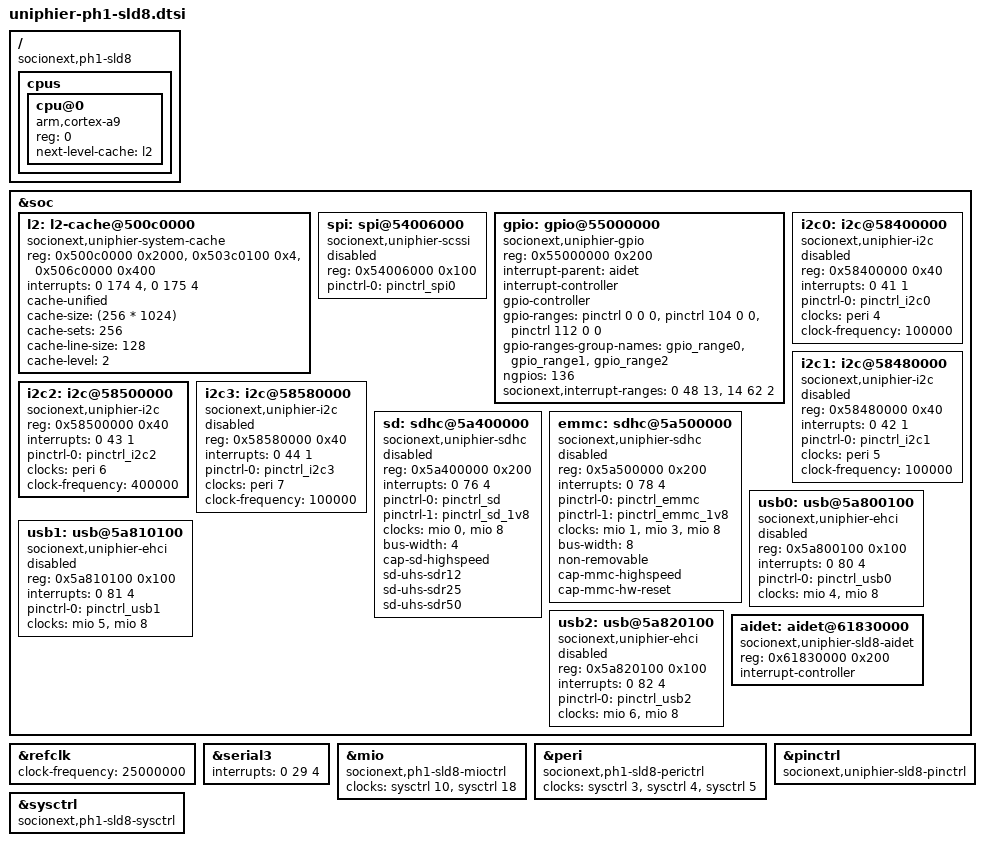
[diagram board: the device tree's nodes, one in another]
// SPDX-License-Identifier: GPL-2.0+ OR MIT
//
// Device Tree Source for UniPhier PH1-sLD8 SoC
//
// Copyright (C) 2015-2016 Socionext Inc.
//   Author: Masahiro Yamada <yamada.masahiro@socionext.com>

#include "uniphier-common32.dtsi"

/ {
	compatible = "socionext,ph1-sld8";

	cpus {
		#address-cells = <1>;
		#size-cells = <0>;

		cpu@0 {
			device_type = "cpu";
			compatible = "arm,cortex-a9";
			reg = <0>;
			next-level-cache = <&l2>;
		};
	};
};

&soc {
	l2: l2-cache@500c0000 {
		compatible = "socionext,uniphier-system-cache";
		reg = <0x500c0000 0x2000>, <0x503c0100 0x4>, <0x506c0000 0x400>;
		interrupts = <0 174 4>, <0 175 4>;
		cache-unified;
		cache-size = <(256 * 1024)>;
		cache-sets = <256>;
		cache-line-size = <128>;
		cache-level = <2>;
	};

	spi: spi@54006000 {
		compatible = "socionext,uniphier-scssi";
		status = "disabled";
		reg = <0x54006000 0x100>;
		pinctrl-names = "default";
		pinctrl-0 = <&pinctrl_spi0>;
	};

	gpio: gpio@55000000 {
		compatible = "socionext,uniphier-gpio";
		reg = <0x55000000 0x200>;
		interrupt-parent = <&aidet>;
		interrupt-controller;
		#interrupt-cells = <2>;
		gpio-controller;
		#gpio-cells = <2>;
		gpio-ranges = <&pinctrl 0 0 0>,
			      <&pinctrl 104 0 0>,
			      <&pinctrl 112 0 0>;
		gpio-ranges-group-names = "gpio_range0",
					  "gpio_range1",
					  "gpio_range2";
		ngpios = <136>;
		socionext,interrupt-ranges = <0 48 13>, <14 62 2>;
	};

	i2c0: i2c@58400000 {
		compatible = "socionext,uniphier-i2c";
		status = "disabled";
		reg = <0x58400000 0x40>;
		#address-cells = <1>;
		#size-cells = <0>;
		interrupts = <0 41 1>;
		pinctrl-names = "default";
		pinctrl-0 = <&pinctrl_i2c0>;
		clocks = <&peri 4>;
		clock-frequency = <100000>;
	};

	i2c1: i2c@58480000 {
		compatible = "socionext,uniphier-i2c";
		status = "disabled";
		reg = <0x58480000 0x40>;
		#address-cells = <1>;
		#size-cells = <0>;
		interrupts = <0 42 1>;
		pinctrl-names = "default";
		pinctrl-0 = <&pinctrl_i2c1>;
		clocks = <&peri 5>;
		clock-frequency = <100000>;
	};

	/* chip-internal connection for DMD */
	i2c2: i2c@58500000 {
		compatible = "socionext,uniphier-i2c";
		reg = <0x58500000 0x40>;
		#address-cells = <1>;
		#size-cells = <0>;
		interrupts = <0 43 1>;
		pinctrl-names = "default";
		pinctrl-0 = <&pinctrl_i2c2>;
		clocks = <&peri 6>;
		clock-frequency = <400000>;
	};

	i2c3: i2c@58580000 {
		compatible = "socionext,uniphier-i2c";
		status = "disabled";
		reg = <0x58580000 0x40>;
		#address-cells = <1>;
		#size-cells = <0>;
		interrupts = <0 44 1>;
		pinctrl-names = "default";
		pinctrl-0 = <&pinctrl_i2c3>;
		clocks = <&peri 7>;
		clock-frequency = <100000>;
	};

	sd: sdhc@5a400000 {
		compatible = "socionext,uniphier-sdhc";
		status = "disabled";
		reg = <0x5a400000 0x200>;
		interrupts = <0 76 4>;
		pinctrl-names = "default", "1.8v";
		pinctrl-0 = <&pinctrl_sd>;
		pinctrl-1 = <&pinctrl_sd_1v8>;
		clock-names = "host", "dmac";
		clocks = <&mio 0>, <&mio 8>;
		bus-width = <4>;
		cap-sd-highspeed;
		sd-uhs-sdr12;
		sd-uhs-sdr25;
		sd-uhs-sdr50;
	};

	emmc: sdhc@5a500000 {
		compatible = "socionext,uniphier-sdhc";
		status = "disabled";
		reg = <0x5a500000 0x200>;
		interrupts = <0 78 4>;
		pinctrl-names = "default", "1.8v";
		pinctrl-0 = <&pinctrl_emmc>;
		pinctrl-1 = <&pinctrl_emmc_1v8>;
		clock-names = "host", "hw-reset", "dmac";
		clocks = <&mio 1>, <&mio 3>, <&mio 8>;
		bus-width = <8>;
		non-removable;
		cap-mmc-highspeed;
		cap-mmc-hw-reset;
	};

	usb0: usb@5a800100 {
		compatible = "socionext,uniphier-ehci", "generic-ehci";
		status = "disabled";
		reg = <0x5a800100 0x100>;
		interrupts = <0 80 4>;
		pinctrl-names = "default";
		pinctrl-0 = <&pinctrl_usb0>;
		clocks = <&mio 4>, <&mio 8>;
	};

	usb1: usb@5a810100 {
		compatible = "socionext,uniphier-ehci", "generic-ehci";
		status = "disabled";
		reg = <0x5a810100 0x100>;
		interrupts = <0 81 4>;
		pinctrl-names = "default";
		pinctrl-0 = <&pinctrl_usb1>;
		clocks = <&mio 5>, <&mio 8>;
	};

	usb2: usb@5a820100 {
		compatible = "socionext,uniphier-ehci", "generic-ehci";
		status = "disabled";
		reg = <0x5a820100 0x100>;
		interrupts = <0 82 4>;
		pinctrl-names = "default";
		pinctrl-0 = <&pinctrl_usb2>;
		clocks = <&mio 6>, <&mio 8>;
	};

	aidet: aidet@61830000 {
		compatible = "socionext,uniphier-sld8-aidet";
		reg = <0x61830000 0x200>;
		interrupt-controller;
		#interrupt-cells = <2>;
	};
};

&refclk {
	clock-frequency = <25000000>;
};

&serial3 {
	interrupts = <0 29 4>;
};

&mio {
	compatible = "socionext,ph1-sld8-mioctrl";
	clock-names = "stdmac", "ehci";
	clocks = <&sysctrl 10>, <&sysctrl 18>;
};

&peri {
	compatible = "socionext,ph1-sld8-perictrl";
	clock-names = "uart", "i2c", "spi";
	clocks = <&sysctrl 3>, <&sysctrl 4>,, <&sysctrl 5>;
};

&pinctrl {
	compatible = "socionext,uniphier-sld8-pinctrl";
};

&sysctrl {
	compatible = "socionext,ph1-sld8-sysctrl";
};
